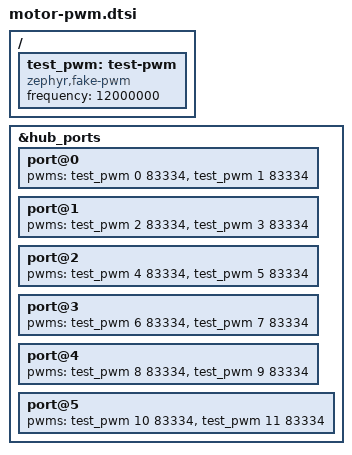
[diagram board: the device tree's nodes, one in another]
// SPDX-License-Identifier: Apache-2.0
/ {
	test_pwm: test-pwm {
		compatible = "zephyr,fake-pwm";
		#pwm-cells = <2>;
		frequency = <12000000>;
	};
};
&hub_ports {
	port@0 { pwms = <&test_pwm 0 83334>, <&test_pwm 1 83334>; };
	port@1 { pwms = <&test_pwm 2 83334>, <&test_pwm 3 83334>; };
	port@2 { pwms = <&test_pwm 4 83334>, <&test_pwm 5 83334>; };
	port@3 { pwms = <&test_pwm 6 83334>, <&test_pwm 7 83334>; };
	port@4 { pwms = <&test_pwm 8 83334>, <&test_pwm 9 83334>; };
	port@5 { pwms = <&test_pwm 10 83334>, <&test_pwm 11 83334>; };
};
